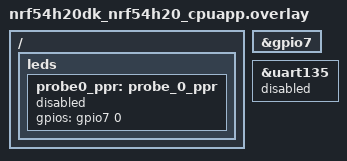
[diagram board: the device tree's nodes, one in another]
/* SPDX-License-Identifier: Apache-2.0 */

/*
 * Only vpr_launcher (cpuapp side) emits UICR.PERIPHCONF entries in a cpuppr
 * or cpuflpr build, so resources the VPR core uses must be claimed here.
 * "reserved" grants them without cpuapp using them; the probe pin must sit
 * under a gpio-leds node so that "gpios" is decoded as a phandle-array.
 */

/ {
	leds {
		probe0_ppr: probe_0_ppr {
			gpios = <&gpio7 0 GPIO_ACTIVE_HIGH>;
			status = "reserved";
		};
	};
};

&gpio7 {
	status = "okay";
};

/*
 * Console UART for the VPR core. For PPR the nordic-ppr snippet also routes
 * its IRQ to PPR; FLPR uses it in polling mode, so the IRQ stays on cpuapp.
 */
&uart135 {
	status = "reserved";
};
